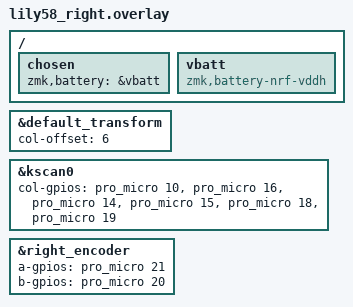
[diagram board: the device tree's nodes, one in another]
/*
 * Copyright (c) 2020 Pete Johanson
 *
 * SPDX-License-Identifier: MIT
 */

#include "lily58.dtsi"

&default_transform {
    col-offset = <6>;
};

&kscan0 {
    col-gpios
        = <&pro_micro 10 GPIO_ACTIVE_HIGH>
        , <&pro_micro 16 GPIO_ACTIVE_HIGH>
        , <&pro_micro 14 GPIO_ACTIVE_HIGH>
        , <&pro_micro 15 GPIO_ACTIVE_HIGH>
        , <&pro_micro 18 GPIO_ACTIVE_HIGH>
        , <&pro_micro 19 GPIO_ACTIVE_HIGH>
        ;
};
&right_encoder {
    status = "okay";
    /* A and B swapped from lily58.dtsi: on Sina's board the stock order made
     * clockwise count as counter-clockwise (scrolling up instead of down) */
    a-gpios = <&pro_micro 21 (GPIO_ACTIVE_HIGH | GPIO_PULL_UP)>;
    b-gpios = <&pro_micro 20 (GPIO_ACTIVE_HIGH | GPIO_PULL_UP)>;
};
/ {
    chosen {
      zmk,battery = &vbatt;
    };

    vbatt: vbatt {
        compatible = "zmk,battery-nrf-vddh";
    };
};
